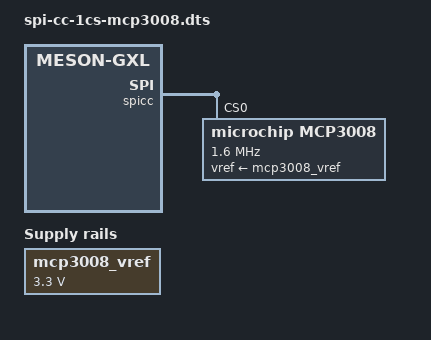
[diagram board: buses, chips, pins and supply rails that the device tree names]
// SPDX-License-Identifier: (GPL-2.0-or-later OR MIT)
/*
 * Copyright (c) Libre Computer Project
 */
/*
 * Summary: Device Tree Overlay to enable MCP3008 ADC
 *
 * Requires: spi-cc-1cs
 */
/dts-v1/;
/plugin/;

#include <dt-bindings/gpio/gpio.h>
#include <dt-bindings/gpio/meson-gxl-gpio.h>

/ {
	compatible = "libre-computer,aml-s905x-cc",
		"libretech,aml-s905x-cc",
		"libre-computer,aml-s905x-cc-v2",
		"libretech,aml-s905x-cc-v2",
		"libre-computer,aml-s905x-cc-v3",
		"libretech,aml-s905x-cc-v3",
		"amlogic,s905x",
		"amlogic,meson-gxl";

	/*
	 * VREF is tied to the header's 3.3V on the usual breakouts. Without a
	 * vref-supply the driver gets the dummy regulator, raw reads work and
	 * in_voltage_scale fails (regulator_get_voltage on the dummy).
	 */
	fragment@1 {
		target-path = "/";

		__overlay__ {
			mcp3008_vref: regulator-mcp3008-vref {
				compatible = "regulator-fixed";
				regulator-name = "MCP3008_VREF";
				regulator-min-microvolt = <3300000>;
				regulator-max-microvolt = <3300000>;
				regulator-always-on;
			};
		};
	};

	fragment@0 {
		target = <&spicc>;

		__overlay__ {
			mcp3008@0 {
				compatible = "microchip,mcp3008";
				reg = <0>;
				spi-max-frequency = <1600000>;
				vref-supply = <&mcp3008_vref>;
				status = "okay";
			};
		};
	};
};
